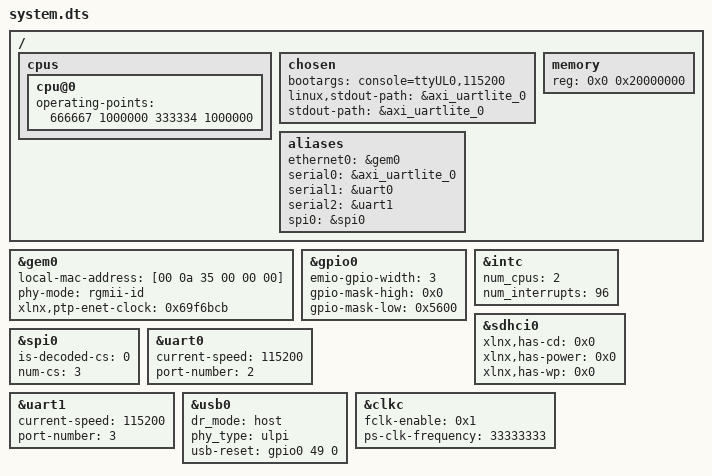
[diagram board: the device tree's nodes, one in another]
/*
 * CAUTION: This file is automatically generated by Xilinx.
 * Version:  
 * Today is: Fri Dec 02 14:18:20 2016
*/


/dts-v1/;
/include/ "zynq-7000.dtsi"
/include/ "pl.dtsi"
/ {
	cpus {
		cpu@0 {
			operating-points = <666667 1000000 333334 1000000>;
		};
	};
	chosen {
		bootargs = "console=ttyUL0,115200";
		linux,stdout-path = &axi_uartlite_0;
		stdout-path = &axi_uartlite_0;
	};
	aliases {
		ethernet0 = &gem0;
		serial0 = &axi_uartlite_0;
		serial1 = &uart0;
		serial2 = &uart1;
		spi0 = &spi0;
	};
	memory {
		device_type = "memory";
		reg = <0x0 0x20000000>;
	};
};
&gem0 {
	local-mac-address = [00 0a 35 00 00 00];
	phy-mode = "rgmii-id";
	status = "okay";
	xlnx,ptp-enet-clock = <0x69f6bcb>;
};
&gpio0 {
	emio-gpio-width = <3>;
	gpio-mask-high = <0x0>;
	gpio-mask-low = <0x5600>;
};
&intc {
	num_cpus = <2>;
	num_interrupts = <96>;
};
&sdhci0 {
	status = "okay";
	xlnx,has-cd = <0x0>;
	xlnx,has-power = <0x0>;
	xlnx,has-wp = <0x0>;
};
&spi0 {
	is-decoded-cs = <0>;
	num-cs = <3>;
	status = "okay";
};
&uart0 {
	current-speed = <115200>;
	device_type = "serial";
	port-number = <2>;
	status = "okay";
};
&uart1 {
	current-speed = <115200>;
	device_type = "serial";
	port-number = <3>;
	status = "okay";
};
&usb0 {
	dr_mode = "host";
	phy_type = "ulpi";
	status = "okay";
	usb-reset = <&gpio0 49 0>;
};
&clkc {
	fclk-enable = <0x1>;
	ps-clk-frequency = <33333333>;
};
